# RTS591x register map
Vendor: Realtek Semiconductor Corp.; Series: RTS591x Series; File version: 1.0
CPU: ARMV8MML r0p0, little endian, MPU, FPU, VTOR, 3 interrupt priority bits, 4 SAU regions
Registers are 32-bit, read-write, reset 0x0 unless marked. A register's access mark holds for its fields unless they carry their own. Offsets are from the block's base; [hi:lo] are bit positions; 'fields as' and 'values as' point back to an identical list.

## SPISLV — SPI Slave Controller
Base 0x40010500
0x00 RXSTRADDR — RX START ADDRESS REGISTER
0x04 RXENDADDR — RX END ADDRESS REGISTER
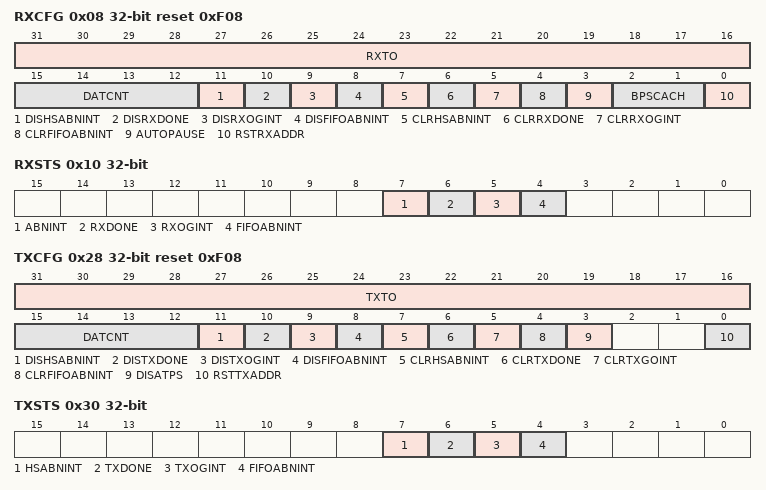
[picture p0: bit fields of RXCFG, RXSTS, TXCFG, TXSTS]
0x08 RXCFG reset 0xF08 — RX CONTROL REGISTER
  [31:16] RXTO — Time-out Of Rx Cache
  [15:12] DATCNT — Every DATTHS^2 byte will trigger data goinh interrupt
  [11] DISHSABNINT — Enable/disable Buffer Handshake Abnormal Interrupt
    0=ENABLE (Enable buffer handshake abnormal interrupt); 1=DISABLE (Disable buffer handshake abnormal interrupt)
  [10] DISRXDONE — Enable/disable Data Transfer Done Interrupt
    0=ENABLE (Enable data transfer done interrupt); 1=DISABLE (Disable data transfer done interrupt)
  [9] DISRXOGINT — Enable/disable Data Ongoing Interrupt
    0=ENABLE (Enable data ongoing interrupt); 1=DISABLE (Disable data ongoing interrupt)
  [8] DISFIFOABNINT — Enable/disable FIFO abnormal interrupt
    0=ENABLE (Enable FIFO abnormal interrupt); 1=DISABLE (Disable FIFO abnormal interrupt)
  [7] CLRHSABNINT — Clear buffer handshake abnormal interrupt flag
    0=DO_NOTHING; 1=CLEAR (Clear buffer handshake abnormal interrupt flag)
  [6] CLRRXDONE — Clear data transfer done interrupt flag
    0=DO_NOTHING; 1=CLEAR (Clear data transfer done interrupt flag)
  [5] CLRRXOGINT — Clear data ongoing interrupt flag
    0=DO_NOTHING; 1=CLEAR (Clear data ongoing interrupt flag)
  [4] CLRFIFOABNINT — Clear FIFO Abnormal Interrupt Flag
    0=DO_NOTHING; 1=CLEAR (Clear FIFO abnormal interrupt flag)
  [3] AUTOPAUSE — Disable Auto-pause Function
    0=ENABLE (Block consequent data after abnormal IRQ is launched); 1=DISANLE (Keep tx or rx consequent data after abnormal IRQ is launched)
  [2:1] BPSCACH — Debug Use Only
  [0] RSTRXADDR — Set Start Address Into Raw-mode Next Address
    0=DO_NOTHING; 1=RESET (Set start address into Raw-Mode next address)
0x10 RXSTS ro — RX INTERRUPT STATUS REGISTER
  [7] ABNINT — Buffer Handshake Abnormal Interrupt Flag
    0=NOT_OCCURRED (No buffer handshake abnormal interrupt is occurred); 1=OCCURRED (Buffer handshake abnormal interrupt is occurred)
  [6] RXDONE — Data Transfer Done Interrupt Flag
    0=NOT_OCCURRED (No Data transfer done interrupt is occurred); 1=OCCURRED (Data transfer done interrupt is occurred)
  [5] RXOGINT — Data Ongoing Interrupt Flag
    0=NOT_OCCURRED (No Data ongoing interrupt is occurred); 1=OCCURRED (Data ongoing interrupt is occurred)
  [4] FIFOABNINT — FIFO abnormal interrupt flag
    0=NOT_OCCURRED (No FIFO abnormal interrupt is occurred); 1=OCCURRED (FIFO abnormal interrupt is occurred)
0x14 RXCURRADDR ro — CURRENT RX ADDRESS REGISTER
0x20 TXSTRADDR — TX START ADDRESS REGISTER
0x24 TXENDADDR — TX END ADDRESS REGISTER
0x28 TXCFG reset 0xF08 — TX CONTROL REGISTER
  [31:16] TXTO — Time-out of TX Cache
  [15:12] DATCNT — Every DATTHS^2 byte will trigger data goinh interrupt
  [11] DISHSABNINT — Enable/disable Buffer Handshake Abnormal Interrupt
    values as RXCFG.DISHSABNINT
  [10] DISTXDONE — Enable/disable Data Transfer Done Interrupt
    values as RXCFG.DISRXDONE
  [9] DISTXOGINT — Enable/disable Data Ongoing Interrupt
    values as RXCFG.DISRXOGINT
  [8] DISFIFOABNINT — Enable/disable FIFO Abnormal Interrupt
    values as RXCFG.DISFIFOABNINT
  [7] CLRHSABNINT — Clear buffer handshake abnormal interrupt flag
    values as RXCFG.CLRHSABNINT
  [6] CLRTXDONE — Clear Data Transfer Done Interrupt Flag
    values as RXCFG.CLRRXDONE
  [5] CLRTXGOINT — Clear Data Ongoing Interrupt Flag
    0=DO_NOTHING; 1=CLEAR (Clear data ongoing interrupt flag)
  [4] CLRFIFOABNINT — Clear Fifo Abnormal Interrupt Flag
    0=DO_NOTHING; 1=CLEAR (Clear FIFO abnormal interrupt flag)
  [3] DISATPS — Disable Auto-pause Function
    0=ENABLE (Block consequent data after abnormal IRQ is launched); 1=DISABLE (Keep tx or rx consequent data after abnormal IRQ is launched)
  [0] RSTTXADDR — Set Start Address Into Raw-mode Next Address
    values as RXCFG.RSTRXADDR
0x30 TXSTS ro — TX INTERRUPT STATUS REGISTER
  [7] HSABNINT — Buffer Handshake Abnormal Interrupt Flag
    values as RXSTS.ABNINT
  [6] TXDONE — Data Transfer Done Interrupt Flag
    values as RXSTS.RXDONE
  [5] TXOGINT — Data Ongoing Interrupt Flag
    values as RXSTS.RXOGINT
  [4] FIFOABNINT — FIFO Abnormal Interrupt Flag
    values as RXSTS.FIFOABNINT
0x34 TXCURRADDR ro — CURRENT TX ADDRESS REGISTER
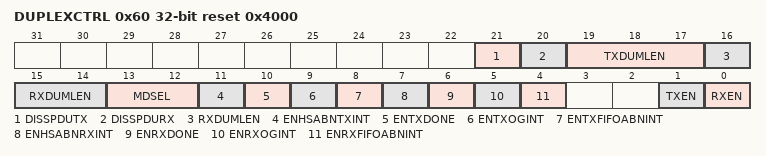
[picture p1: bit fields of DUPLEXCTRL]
0x60 DUPLEXCTRL reset 0x4000 — DUPLEX SETTING CONTROL REGISTER
  [21] DISSPDUTX — Control TX 4-phase Handshake
    0=DISABLE (Disable TX 4-phase handshake); 1=ENABLE (Enable TX 4-phase handshake)
  [20] DISSPDURX — Control RX 4-phase Handshake
    0=DISABLE (Disable RX 4-phase handshake); 1=ENABLE (Enable 4-phase handshake)
  [19:17] TXDUMLEN — Control TX Dummy Byte Count
  [16:14] RXDUMLEN — Control RX Dummy Byte Count
  [13:12] MDSEL — Firmware-controlled Switch Of Command Mode Raw-data Amode
  [11] ENHSABNTXINT — Enable/disable Tx Buffer Handshake Abnormal Interrupt
    0=DISABLE (Disable TX buffer handshake abnormal interrupt); 1=ENABLE (Enable TX buffer handshake abnormal interrupt)
  [10] ENTXDONE — Enable/disable TX Data Transfer Done Interrupt
    0=DISABLE (Disable TX data transfer done interrupt); 1=ENABLE (Enable TX data transfer done interrupt)
  [9] ENTXOGINT — Enable/disable TX Data Ongoing Interrupt
    0=DISABLE (Disable TX data ongoing interrupt); 1=ENABLE (Enable TX data ongoing interrupt)
  [8] ENTXFIFOABNINT — Enable/disable TX FIFO Abnormal Interrupt
    0=DISABLE (Disable TX FIFO abnormal interrupt); 1=ENABLE (Enable TX FIFO abnormal interrupt)
  [7] ENHSABNRXINT — Enable/disable Rx Buffer Handshake Abnormal Interrupt
    0=DISABLE (Disable RX buffer handshake abnormal interrupt); 1=ENABLE (DisEnableable RX buffer handshake abnormal interrupt)
  [6] ENRXDONE — Enable/disable Rx Data Transfer Done Interrupt
    0=DISABLE (Disable RX data transfer done interrupt); 1=ENABLE (Enable RX data transfer done interrupt)
  [5] ENRXOGINT — Enable/disable RX Data Ongoing Interrupt
    0=DISABLE (Disable RX data ongoing interrupt); 1=ENABLE (Enable RX data ongoing interrupt)
  [4] ENRXFIFOABNINT — Enable/disable RX FIFO Abnormal Interrupt
    0=DISABLE (Disable RX FIFO abnormal interrupt); 1=ENABLE (Enable RX FIFO abnormal interrupt)
  [1] TXEN — Enable/disable TX function
    0=ENABLE (Enable TX function); 1=DISABLE (Disable TX function)
  [0] RXEN — Enable/disable RX Function
    0=ENABLE (Enable RX function); 1=DISABLE (Disable RX function)
